AUTOSAR XML (schema 4-3-0)
package /ComponentTypes
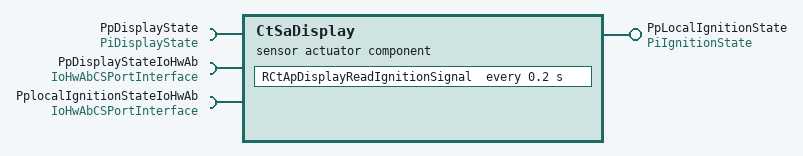
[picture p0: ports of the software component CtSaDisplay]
  sensor actuator sw component type CtSaDisplay
    require port PpDisplayState: required-interface=PiDisplayState
      required-com-specs:
        data-element=DeDisplayBusState, filter=data-filter-type=ALWAYS, init-value=constant-reference=CBackLightDimCtrlInit
        data-element=DeLightOnOffCounter, filter=data-filter-type=ALWAYS, init-value=constant-reference=CUInt32Zero
        data-element=DeOdometerValue, filter=data-filter-type=ALWAYS, init-value=constant-reference=CUInt32Zero
        data-element=DeOdometerWriteRequestPending, filter=data-filter-type=ALWAYS, init-value=constant-reference=CWriteReqNotPending
    require port PpDisplayStateIoHwAb: required-com-specs=[ReadChannel, WriteChannel], required-interface=IoHwAbCSPortInterface
    require port PplocalIgnitionStateIoHwAb: required-com-specs=[ReadChannel, WriteChannel], required-interface=IoHwAbCSPortInterface
    provide port PpLocalIgnitionState: nonqueued-sender-com-spec{data-element=DeIgnitionState, init-value=1}, provided-interface=PiIgnitionState
    behavior CtSaDisplay_InternalBehavior: data-type-mapping=DemoTypeMapping
      4 x data received event:
        DRT_RCtApDisplayBusStateHandling_PiDisplayState_DeDisplayBusState: start-on-event=RCtApDisplayBusStateHandling, data=PpDisplayState.DeDisplayBusState
        DRT_RCtApDisplayLightOnOffHandling_PiDisplayState_DeLightOnOffCounter: start-on-event=RCtApDisplayLightOnOffHandling, data=PpDisplayState.DeLightOnOffCounter
        DRT_RCtApDisplayOdometerValue_PiDisplayState_DeOdometerValue: start-on-event=RCtApDisplayOdometerValue, data=PpDisplayState.DeOdometerValue
        DRT_RCtApDisplayOdometerWriteRequestPending_PiDisplayState_DeOdometerWriteRequestPending: start-on-event=RCtApDisplayOdometerWriteRequestPending, data=PpDisplayState.DeOdometerWriteRequestPending
      timing event TMT_RCtApDisplayReadIgnitionSignal: start-on-event=RCtApDisplayReadIgnitionSignal, period=0.2
      5 x runnable:
        RCtApDisplayBusStateHandling
          data-receive-point-by-arguments:
            access REC_PiDisplayState_DeDisplayBusState: accessed-variable=PpDisplayState.DeDisplayBusState
          sync call SC_PpDisplayStateIoHwAb_WriteChannel: operation=PpDisplayStateIoHwAb.WriteChannel
          sync call SC_PplocalIgnitionStateIoHwAb_ReadChannel: operation=PplocalIgnitionStateIoHwAb.ReadChannel
        RCtApDisplayLightOnOffHandling
          data-receive-point-by-arguments:
            access REC_PiDisplayState_DeLightOnOffCounter: accessed-variable=PpDisplayState.DeLightOnOffCounter
        RCtApDisplayOdometerValue
          data-receive-point-by-arguments:
            access REC_PiDisplayState_DeOdometerValue: accessed-variable=PpDisplayState.DeOdometerValue
        RCtApDisplayOdometerWriteRequestPending
          data-receive-point-by-arguments:
            access REC_PiDisplayState_DeOdometerWriteRequestPending: accessed-variable=PpDisplayState.DeOdometerWriteRequestPending
        RCtApDisplayReadIgnitionSignal
          data-send-points:
            access SEND_PpLocalIgnitionState_DeIgnitionState: accessed-variable=PpLocalIgnitionState.DeIgnitionState
          sync call SC_PplocalIgnitionStateIoHwAb_ReadChannel: operation=PplocalIgnitionStateIoHwAb.ReadChannel
  swc implementation CtSaDisplay_Implementation: behavior=CtSaDisplay_InternalBehavior
